# CKMD register map
Vendor: Texas Instruments
Peripheral module from a debugger description file (folder CC23x0R5).
Registers are 32-bit, access per field, reset 0x0 unless marked. A register's access mark holds for its fields unless they carry their own. Offsets are as the file gives them; lines under a group give offsets from that group; [hi:lo] are bit positions; {n}, {i} and the like mark numbered series; 'fields as' and 'values as' point back to an identical list; <NAME> marks a mode.

## CKMD — Clock Controller
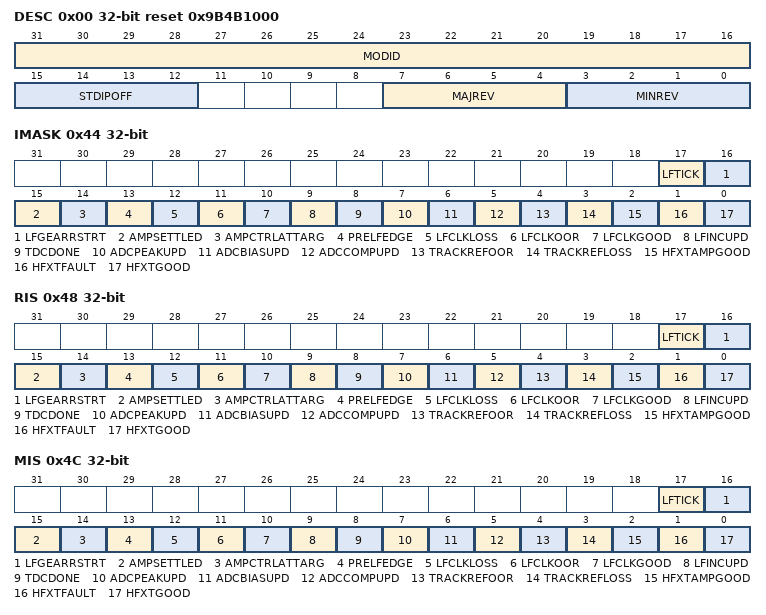
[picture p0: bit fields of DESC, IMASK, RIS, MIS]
0x00 DESC ro reset 0x9B4B1000 — Description Register. This register provides IP module ID, revision information, instance index and standard MMR registers offset.
  [31:16] MODID — Module identifier used to uniquely identify this IP.
  [15:12] STDIPOFF — Standard IP MMR block offset. Standard IP MMRs are the set of from aggregated IRQ registers till DTB. 0: Standard IP MMRs do not exist 0x1-0xF: Standard IP MMRs begin at offset of (64*STDIPOFF from the base IP address) NOTE: This IP does not have DTB as part of the Standard IP MMRs. It uses DTBCTL instead.
  [7:4] MAJREV — Major revision of IP (0-15).
  [3:0] MINREV — Minor revision of IP (0-15).
0x44 IMASK — Interrupt mask. This register selects interrupt sources which are allowed to pass from RIS to MIS when the corresponding bit-fields are set to 1.
  [17] LFTICK rw — 32kHz TICK to RTC and WDT. Either derived from selected LFCLK or generated from CLKULL in absence of LFCLK.
  [16] LFGEARRSTRT rw — LFINC filter gearing restart. Indicates that the LFINC filter restarted gearing. Subsequent LFINC estimates may have higher variation.
  [15] AMPSETTLED rw — HFXT Amplitude compensation - settled Indicates that the amplitude compensation FSM has reached the SETTLED or TCXOMODE state, and the controls configured in HFXTTARG or HFXTDYN are reached.
  [14] AMPCTRLATTARG rw — HFXT Amplitude compensation - controls at target Indicates that the control values configured in HFXTTARG or HFXTDYN are reached. Applies to Q1CAP, Q2CAP and IREF.
  [13] PRELFEDGE rw — Pre-LF clock edge detect. Indicates that a positive edge occured on the selected pre-LF clock LFCLKSEL.PRE. Can be used by software to confirm that a LF clock source is running and within the expected frequency, before selecting it as the main LF clock source.
  [12] LFCLKLOSS rw — LF clock is lost. Indicates that no LF clock edge occured for ~49us (~1.6 times nominal period). The system will automatically fall-back to generating LFTICK based on CLKULL, to avoid timing corruption. Note that this signal is NOT related to the analog LF clock-loss detector which can reset the device during STANDBY.
  [11] LFCLKOOR rw — LF clock period out-of-range. Indicates that a LF clock period was measured to be out-of-range, according to LFQUALCTL.MAXERR.
  [10] LFCLKGOOD rw — LF clock good. Indicates that the LF clock is good, according to the configuration in LFQUALCTL.
  [9] LFINCUPD rw — LFINC updated. Indicates that a new LFINC measurement value is available in LFCLKSTAT.LFINC.
  [8] TDCDONE rw — TDC done event. Indicates that the TDC measurement is done.
  [7] ADCPEAKUPD rw — HFXT-ADC PEAK measurement update event. Indicates that the HFXT-ADC PEAK measurement is done.
  [6] ADCBIASUPD rw — HFXT-ADC BIAS measurement update event. Indicates that the HFXT-ADC BIAS measurement is done.
  [5] ADCCOMPUPD rw — HFXT-ADC comparison update event. Indicates that the HFXT-ADC comparison is done.
  [4] TRACKREFOOR rw — Out-of-range indication from the tracking loop. Indicates that the selected reference clock frequency of the tracking loop is out-of-range.
  [3] TRACKREFLOSS rw — Clock loss indication from the tracking loop. Indicates that the selected reference clock of the tracking loop is lost.
  [2] HFXTAMPGOOD rw — HFXT amplitude good indication.
  [1] HFXTFAULT rw — HFXT fault indication. Indicates that HFXT did not start correctly, or its frequency is too low. HFXT will not recover from this fault and has to be restarted. This is only a one-time check at HFXT startup.
  [0] HFXTGOOD rw — HFXT good indication. Indicates that HFXT started correctly. The frequency is not necessarily good enough for radio operation. This is only a one-time check at HFXT startup.
0x48 RIS ro — Raw interrupt status. This register reflects the state of all pending interrupts, regardless of masking. This register allows the user to implement a poll scheme. A flag set in this register can be cleared by writing 1 to the corresponding ICLR register bit.
  [17] LFTICK — 32kHz TICK to RTC and WDT. Either derived from selected LFCLK or generated from CLKULL in absence of LFCLK.
  [16] LFGEARRSTRT — LFINC filter gearing restart. Indicates that the LFINC filter restarted gearing. Subsequent LFINC estimates may have higher variation.
  [15] AMPSETTLED — HFXT Amplitude compensation - settled Indicates that the amplitude compensation FSM has reached the SETTLED or TCXOMODE state, and the controls configured in HFXTTARG or HFXTDYN are reached.
  [14] AMPCTRLATTARG — HFXT Amplitude compensation - controls at target Indicates that the control values configured in HFXTTARG or HFXTDYN are reached. Applies to Q1CAP, Q2CAP and IREF.
  [13] PRELFEDGE — Pre-LF clock edge detect. Indicates that a positive edge occured on the selected pre-LF clock LFCLKSEL.PRE. Can be used by software to confirm that a LF clock source is running and within the expected frequency, before selecting it as the main LF clock source.
  [12] LFCLKLOSS — LF clock is lost. Indicates that no LF clock edge occured for ~49us (~1.6 times nominal period). The system will automatically fall-back to generating LFTICK based on CLKULL, to avoid timing corruption. Note that this signal is NOT related to the analog LF clock-loss detector which can reset the device during STANDBY.
  [11] LFCLKOOR — LF clock period out-of-range. Indicates that a LF clock period was measured to be out-of-range, according to LFQUALCTL.MAXERR.
  [10] LFCLKGOOD — LF clock good. Indicates that the LF clock is good, according to the configuration in LFQUALCTL.
  [9] LFINCUPD — LFINC updated. Indicates that a new LFINC measurement value is available in LFCLKSTAT.LFINC.
  [8] TDCDONE — TDC done event. Indicates that the TDC measurement is done.
  [7] ADCPEAKUPD — HFXT-ADC PEAK measurement update event. Indicates that the HFXT-ADC PEAK measurement is done.
  [6] ADCBIASUPD — HFXT-ADC BIAS measurement update event. Indicates that the HFXT-ADC BIAS measurement is done.
  [5] ADCCOMPUPD — HFXT-ADC comparison update event. Indicates that the HFXT-ADC comparison is done.
  [4] TRACKREFOOR — Out-of-range indication from the tracking loop. Indicates that the selected reference clock frequency of the tracking loop is out-of-range.
  [3] TRACKREFLOSS — Clock loss indication from the tracking loop. Indicates that the selected reference clock of the tracking loop is lost.
  [2] HFXTAMPGOOD — HFXT amplitude good indication.
  [1] HFXTFAULT — HFXT fault indication. Indicates that HFXT did not start correctly, or its frequency is too low. HFXT will not recover from this fault and has to be restarted. This is only a one-time check at HFXT startup.
  [0] HFXTGOOD — HFXT good indication. Indicates that HFXT started correctly. The frequency is not necessarily good enough for radio operation. This is only a one-time check at HFXT startup.
0x4C MIS ro — Masked interrupt status. This register is simply a bitwise AND of the contents of IMASK and RIS.*] registers. A flag set in this register can be cleared by writing 1 to the corresponding ICLR register bit.
  fields as RIS
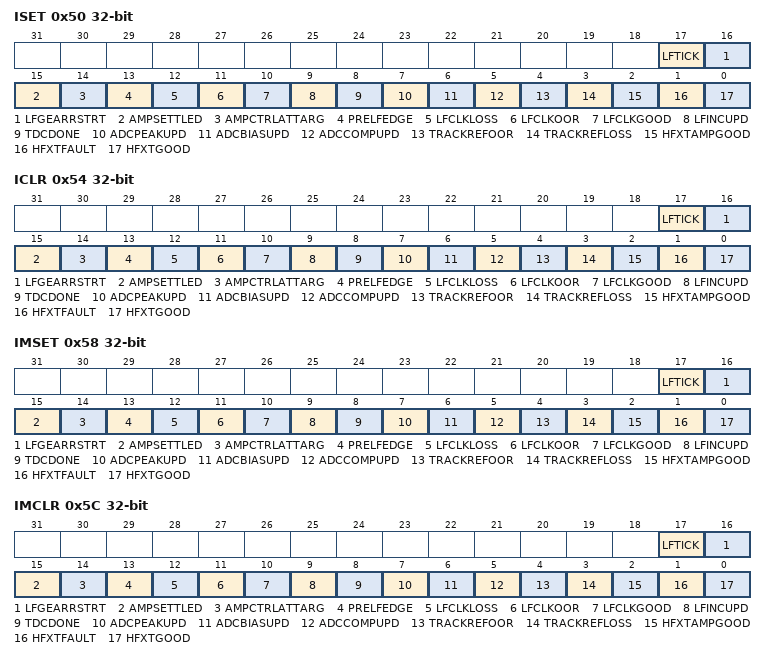
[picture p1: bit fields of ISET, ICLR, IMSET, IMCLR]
0x50 ISET — Interrupt set register. This register can used by software for diagnostics and safety checking purposes. Writing a 1 to a bit in this register will set the event and the corresponding RIS bit also gets set. If the corresponding IMASK bit is set, then the corresponding MIS register bit also gets set.
  [17] LFTICK wo — 32kHz TICK to RTC and WDT. Either derived from selected LFCLK or generated from CLKULL in absence of LFCLK.
  [16] LFGEARRSTRT wo — LFINC filter gearing restart. Indicates that the LFINC filter restarted gearing. Subsequent LFINC estimates may have higher variation.
  [15] AMPSETTLED wo — HFXT Amplitude compensation - settled Indicates that the amplitude compensation FSM has reached the SETTLED or TCXOMODE state, and the controls configured in HFXTTARG or HFXTDYN are reached.
  [14] AMPCTRLATTARG wo — HFXT Amplitude compensation - controls at target Indicates that the control values configured in HFXTTARG.Q1CAP, HFXTTARG.Q2CAP and HFXTTARG.IREF or HFXTDYN.Q1CAP, HFXTDYN.Q2CAP and HFXTDYN.IREF are reached.
  [13] PRELFEDGE wo — Pre-LF clock edge detect. Indicates that a positive edge occured on the selected pre-LF clock LFCLKSEL.PRE. Can be used by software to confirm that a LF clock source is running and within the expected frequency, before selecting it as the main LF clock source.
  [12] LFCLKLOSS wo — LF clock is lost. Indicates that no LF clock edge occured for ~49us (~1.6 times nominal period). The system will automatically fall-back to generating LFTICK based on CLKULL, to avoid timing corruption. Note that this signal is NOT related to the analog LF clock-loss detector which can reset the device during STANDBY.
  [11] LFCLKOOR wo — LF clock period out-of-range. Indicates that a LF clock period was measured to be out-of-range, according to LFQUALCTL.MAXERR.
  [10] LFCLKGOOD wo — LF clock good. Indicates that the LF clock is good, according to the configuration in LFQUALCTL.
  [9] LFINCUPD wo — LFINC updated. Indicates that a new LFINC measurement value is available in LFCLKSTAT.LFINC.
  [8] TDCDONE wo — TDC done event. Indicates that the TDC measurement is done.
  [7] ADCPEAKUPD wo — HFXT-ADC PEAK measurement update event. Indicates that the HFXT-ADC PEAK measurement is done.
  [6] ADCBIASUPD wo — HFXT-ADC BIAS measurement update event. Indicates that the HFXT-ADC BIAS measurement is done.
  [5] ADCCOMPUPD wo — HFXT-ADC comparison update event. Indicates that the HFXT-ADC comparison is done.
  [4] TRACKREFOOR wo — Out-of-range indication from the tracking loop. Indicates that the selected reference clock frequency of the tracking loop is out-of-range.
  [3] TRACKREFLOSS wo — Clock loss indication from the tracking loop. Indicates that the selected reference clock of the tracking loop is lost.
  [2] HFXTAMPGOOD wo — HFXT amplitude good indication.
  [1] HFXTFAULT wo — HFXT fault indication. Indicates that HFXT did not start correctly, or its frequency is too low. HFXT will not recover from this fault and has to be restarted. This is only a one-time check at HFXT startup.
  [0] HFXTGOOD wo — HFXT good indication. Indicates that HFXT started correctly. The frequency is not necessarily good enough for radio operation. This is only a one-time check at HFXT startup.
0x54 ICLR — Interrupt clear register. This register allows software to clear interrupts. Writing a 1 to a bit in this register will clear the event and the corresponding RIS bit also gets cleared. If the corresponding IMASK bit is set, then the corresponding MIS register bit also gets cleared.
  [17] LFTICK wo — 32kHz TICK to RTC and WDT. Either derived from selected LFCLK or generated from CLKULL in absence of LFCLK.
  [16] LFGEARRSTRT wo — LFINC filter gearing restart. Indicates that the LFINC filter restarted gearing. Subsequent LFINC estimates may have higher variation.
  [15] AMPSETTLED wo — HFXT Amplitude compensation - settled Indicates that the amplitude compensation FSM has reached the SETTLED or TCXOMODE state, and the controls configured in HFXTTARG or HFXTDYN are reached.
  [14] AMPCTRLATTARG wo — HFXT Amplitude compensation - controls at target Indicates that the control values configured in HFXTTARG or HFXTDYN are reached. Applies to Q1CAP, Q2CAP and IREF.
  [13] PRELFEDGE wo — Pre-LF clock edge detect. Indicates that a positive edge occured on the selected pre-LF clock LFCLKSEL.PRE. Can be used by software to confirm that a LF clock source is running and within the expected frequency, before selecting it as the main LF clock source.
  [12] LFCLKLOSS wo — LF clock is lost. Indicates that no LF clock edge occured for ~49us (~1.6 times nominal period). The system will automatically fall-back to generating LFTICK based on CLKULL, to avoid timing corruption. Note that this signal is NOT related to the analog LF clock-loss detector which can reset the device during STANDBY.
  [11] LFCLKOOR wo — LF clock period out-of-range. Indicates that a LF clock period was measured to be out-of-range, according to LFQUALCTL.MAXERR.
  [10] LFCLKGOOD wo — LF clock good. Indicates that the LF clock is good, according to the configuration in LFQUALCTL.
  [9] LFINCUPD wo — LFINC updated. Indicates that a new LFINC measurement value is available in LFCLKSTAT.LFINC.
  [8] TDCDONE wo — TDC done event. Indicates that the TDC measurement is done.
  [7] ADCPEAKUPD wo — HFXT-ADC PEAK measurement update event. Indicates that the HFXT-ADC PEAK measurement is done.
  [6] ADCBIASUPD wo — HFXT-ADC BIAS measurement update event. Indicates that the HFXT-ADC BIAS measurement is done.
  [5] ADCCOMPUPD wo — HFXT-ADC comparison update event. Indicates that the HFXT-ADC comparison is done.
  [4] TRACKREFOOR wo — Out-of-range indication from the tracking loop. Indicates that the selected reference clock frequency of the tracking loop is out-of-range.
  [3] TRACKREFLOSS wo — Clock loss indication from the tracking loop. Indicates that the selected reference clock of the tracking loop is lost.
  [2] HFXTAMPGOOD wo — HFXT amplitude good indication.
  [1] HFXTFAULT wo — HFXT fault indication. Indicates that HFXT did not start correctly, or its frequency is too low. HFXT will not recover from this fault and has to be restarted. This is only a one-time check at HFXT startup.
  [0] HFXTGOOD wo — HFXT good indication. Indicates that HFXT started correctly. The frequency is not necessarily good enough for radio operation. This is only a one-time check at HFXT startup.
0x58 IMSET — Interrupt mask set register. Writing a 1 to a bit in this register will set the corresponding IMASK bit.
  fields as ICLR
0x5C IMCLR — Interrupt mask clear register. Writing a 1 to a bit in this register will clear the corresponding IMASK bit.
  fields as ICLR
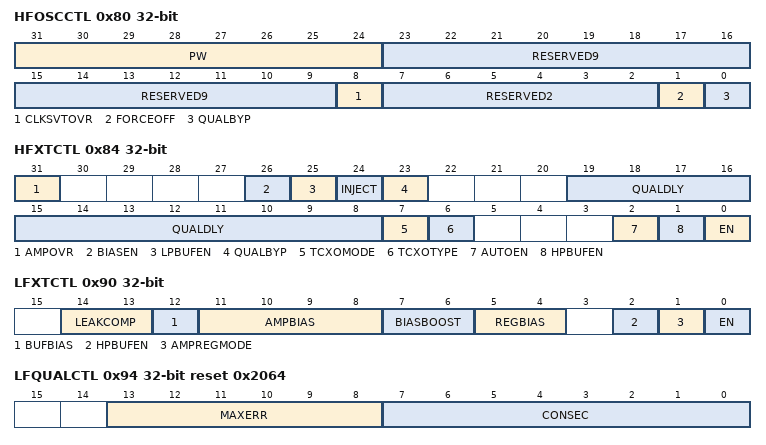
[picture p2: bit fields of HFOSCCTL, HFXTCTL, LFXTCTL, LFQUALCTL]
0x80 HFOSCCTL — Internal. Only to be used through TI provided API.
  [31:24] PW wo — Internal. Only to be used through TI provided API.
  [23:9] RESERVED9 ro — Internal. Only to be used through TI provided API.
  [8] CLKSVTOVR rw — Internal. Only to be used through TI provided API.
    1=HFXT (Internal. Only to be used through TI provided API.); 0=HFOSC (Internal. Only to be used through TI provided API.)
  [7:2] RESERVED2 ro — Internal. Only to be used through TI provided API.
  [1] FORCEOFF rw — Internal. Only to be used through TI provided API.
  [0] QUALBYP rw — Internal. Only to be used through TI provided API.
0x84 HFXTCTL — High frequency crystal control
  [31] AMPOVR rw — Internal. Only to be used through TI provided API.
  [26] BIASEN rw — Internal. Only to be used through TI provided API.
  [25] LPBUFEN rw — Internal. Only to be used through TI provided API.
  [24] INJECT rw — Internal. Only to be used through TI provided API.
  [23] QUALBYP rw — Internal. Only to be used through TI provided API.
  [19:8] QUALDLY rw — Skip potentially unstable clock cycles after enabling HFXT. Number of cycles skipped is 8*QUALDLY.
  [7] TCXOMODE rw — Temperature compensated crystal oscillator mode. Set this bit if a TXCO is connected.
  [6] TCXOTYPE rw — Type of temperature compensated crystal used. Only has effect if TCXOMODE is set.
    1=CMOS (Use with CMOS TCXO); 0=CLIPPEDSINE (Use with clipped-sine TCXO)
  [2] AUTOEN rw — Internal. Only to be used through TI provided API.
  [1] HPBUFEN rw — High performance clock buffer enable. This bit controls the clock output for the RF PLL. It is required for radio operation.
  [0] EN rw — Internal. Only to be used through TI provided API.
0x8C LFOSCCTL — Low frequency oscillator control
  [0] EN rw — LFOSC enable
0x90 LFXTCTL — Low frequency crystal control
  [14:13] LEAKCOMP rw — Leakage compensation control
    3=OFF (No leakage compensation); 1=HALF (Half leakage compensation); 0=FULL (Full leakage compensation)
  [12] BUFBIAS rw — Control the BIAS current of the input amp in LP buffer
    1=MAX (Maximum bias current: 50nA); 0=MIN (Minimum bias current: 25nA)
  [11:8] AMPBIAS rw — Adjust current mirror ratio into oscillator core. This value is depending on crystal and is set by FW. This field uses a 2's complement encoding.
  [7:6] BIASBOOST rw — Boost oscillator amplitude This value depends on the crystal and needs to be configured by Firmware.
  [5:4] REGBIAS rw — Regulation loop bias resistor value This value depends on the crystal and needs to be configured by Firmware.
  [2] HPBUFEN rw — Control the buffer used. In normal operation, low-power buffer is used in all device modes. The high-performance buffer is only used for test purposes.
  [1] AMPREGMODE rw — Amplitude regulation mode
    1=LOOPDIS (Amplitude control loop disabled); 0=LOOPEN (Amplitude control loop enabled)
  [0] EN rw — LFXT enable
0x94 LFQUALCTL reset 0x2064 — Low frequency clock qualification control
  [13:8] MAXERR rw — Maximum LFCLK period error. Value given in microseconds, 3 integer bits + 3 fractional bits.
  [7:0] CONSEC rw — Number of consecutive times the LFCLK period error has to be smaller than MAXERR to be considered "good". Setting this value to 0 will bypass clock qualification, and the "good" indicator will always be 1.
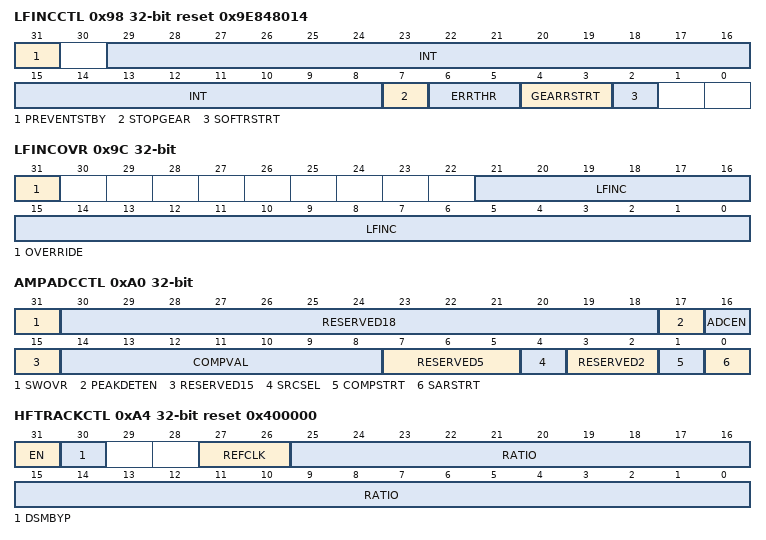
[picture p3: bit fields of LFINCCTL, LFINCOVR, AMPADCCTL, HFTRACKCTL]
0x98 LFINCCTL reset 0x9E848014 — Low frequency time increment control
  [31] PREVENTSTBY rw — Controls if the LFINC filter prevents STANBY entry until settled.
    1=ON (Enable. Prevent STANDBY entry.); 0=OFF (Disable. Do not prevent STANDBY entry.)
  [29:8] INT rw — Integral part of the LFINC filter. This value is updated by Hardware to reflect the current state of the filter. It can also be written to change the current state.
  [7] STOPGEAR rw — Controls the final gear of the LFINC filter.
    1=HIGH (Highest final gear. Best dynamic frequency tracking, but higher variation in filter value.); 0=LOW (Lowest final gear. Best settling, but less dynamic frequency tracking.)
  [6:5] ERRTHR rw — Controls the threshold for gearing restart of the LFINC filter. Only effective if GEARRSTRT is not ONETHR or TWOTHR.
    3=SMALL (Restart gearing on small error. Potentially more false restarts, faster response on small frequency shifts.); 2=MIDSMALL (Middle value towards SMALL.); 1=MIDLARGE (Middle value towards LARGE.); 0=LARGE (Restart gearing on large error. Fewer false restarts, slower response on small frequency shifts.)
  [4:3] GEARRSTRT rw — Controls gearing restart of the LFINC filter.
    2=TWOTHR (Restart gearing when the error accumulator crosses the threshold twice in a row.); 1=ONETHR (Restart gearing when the error accumulator crosses the threshold once.); 0=NEVER (Never restart gearing. Very stable filter value, but very slow response on frequency changes.)
  [2] SOFTRSTRT rw — Use a higher gear after re-enabling / wakeup. The filter will require 16-24 LFCLK periods to settle (depending on STOPGEAR), but may respond faster to frequency changes during STANDBY.
    1=ON (Use soft gearing restarts); 0=OFF (Don't use soft gearing restarts)
0x9C LFINCOVR — Low frequency time increment override control
  [31] OVERRIDE rw — Override LF increment Use the value provided in LFINC instead of the value calculated by Hardware.
  [21:0] LFINC rw — LF increment value This value is used when OVERRIDE is set to 1. Otherwise the value is calculated automatically.
0xA0 AMPADCCTL — Internal. Only to be used through TI provided API.
  [31] SWOVR rw — Internal. Only to be used through TI provided API.
  [30:18] RESERVED18 ro — Internal. Only to be used through TI provided API.
  [17] PEAKDETEN rw — Internal. Only to be used through TI provided API.
    1=ENABLE (Internal. Only to be used through TI provided API.); 0=DISABLE (Internal. Only to be used through TI provided API.)
  [16] ADCEN rw — Internal. Only to be used through TI provided API.
    values as PEAKDETEN
  [15] RESERVED15 ro — Internal. Only to be used through TI provided API.
  [14:8] COMPVAL rw — Internal. Only to be used through TI provided API.
  [7:5] RESERVED5 ro — Internal. Only to be used through TI provided API.
  [4] SRCSEL rw — Internal. Only to be used through TI provided API.
    1=PEAK (Internal. Only to be used through TI provided API.); 0=BIAS (Internal. Only to be used through TI provided API.)
  [3:2] RESERVED2 ro — Internal. Only to be used through TI provided API.
  [1] COMPSTRT rw — Internal. Only to be used through TI provided API.
  [0] SARSTRT rw — Internal. Only to be used through TI provided API.
0xA4 HFTRACKCTL reset 0x400000 — High frequency tracking loop control
  [31] EN rw — Enable tracking loop.
  [30] DSMBYP rw — Bypass Delta-Sigma-Modulation of fine trim.
  [27:26] REFCLK rw — Select the reference clock for the tracking loop. Change only while the tracking loop is disabled.
    2=GPI (Select GPI as reference clock.); 1=LRF (Select LRF reference clock.); 0=HFXT (Select HFXT as reference clock.)
  [25:0] RATIO rw — Reference clock ratio. RATIO = 24MHz / (2*reference-frequency) * 2^24 Commonly used reference clock frequencies are provided as enumerations.
    0x3000000=REF4M (Use for 4MHz reference clock); 0x1800000=REF8M (Use for 8MHz reference clock); 0x400000=REF48M (Use for 48MHz reference clock)
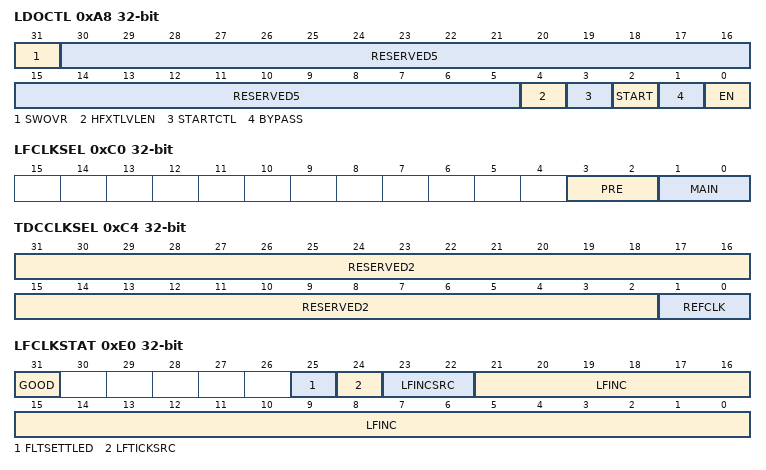
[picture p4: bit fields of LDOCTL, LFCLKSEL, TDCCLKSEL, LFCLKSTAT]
0xA8 LDOCTL — Internal. Only to be used through TI provided API.
  [31] SWOVR rw — Internal. Only to be used through TI provided API.
  [30:5] RESERVED5 ro — Internal. Only to be used through TI provided API.
  [4] HFXTLVLEN rw — Internal. Only to be used through TI provided API.
  [3] STARTCTL rw — Internal. Only to be used through TI provided API.
  [2] START rw — Internal. Only to be used through TI provided API.
  [1] BYPASS rw — Internal. Only to be used through TI provided API.
  [0] EN rw — Internal. Only to be used through TI provided API.
0xAC NABIASCTL — Nanoamp-bias control
  [0] EN rw — Enable nanoamp-bias
0xB0 LFMONCTL — Low-frequency clock-monitor control
  [0] EN rw — Enable LFMONITOR. Enable only after a LF clock source has been selected, enabled and is stable. If LFMONITOR detects a clock loss, the system will be reset.
0xC0 LFCLKSEL — Low frequency clock selection
  [3:2] PRE rw — Select low frequency clock source for the PRELFCLK interrupt. Can be used by Software to confirm that the clock is running and it's frequency is good, before selecting it in MAIN.
    3=EXTLF (External LF clock through GPI.); 2=LFXT (Low frequency crystal oscillator); 1=LFOSC (Low frequency on-chip oscillator); 0=NONE (No clock. Output will be tied low.)
  [1:0] MAIN rw — Select the main low frequency clock source. If running, this clock will be used to generate LFTICK and as CLKULL during STANDBY. If not running, LFTICK will be generated from HFOSC and STANDBY entry will be prevented.
    3=EXTLF (External LF clock through GPI.); 2=LFXT (Low frequency crystal oscillator); 1=LFOSC (Low frequency on-chip oscillator); 0=FAKE (No LF clock selected. LFTICK will be generated from HFOSC, STANDBY entry will be prevented.)
0xC4 TDCCLKSEL — Internal. Only to be used through TI provided API.
  [31:2] RESERVED2 ro — Internal. Only to be used through TI provided API.
  [1:0] REFCLK rw — Internal. Only to be used through TI provided API.
    3=GPI (Internal. Only to be used through TI provided API.); 2=CLKULL (Internal. Only to be used through TI provided API.); 1=CLKSVT (Internal. Only to be used through TI provided API.); 0=NONE (Internal. Only to be used through TI provided API.)
0xC8 ADCCLKSEL — ADC clock selection
  [1:0] SRC rw — Select ADC clock source Change only while ADC is disabled.
    1=HFXT (48MHz HFXT); 0=CLKSVT (48MHz CLKSVT)
0xE0 LFCLKSTAT ro — Low-frequency clock status
  [31] GOOD — Low frequency clock good Note: This is only a coarse frequency check based on LFQUALCTL. The clock may not be accurate enough for timing purposes.
  [25] FLTSETTLED — LFINC filter is running and settled.
  [24] LFTICKSRC — Source of LFTICK.
    1=FAKE (LFTICK generated from CLKULL (LFCLK not available)); 0=LFCLK (LFTICK generated from the selected LFCLK)
  [23:22] LFINCSRC — Source of LFINC used by the RTC. This value depends on LFINCOVR.OVERRIDE, LF clock availability, HF tracking loop status and the device state (ACTIVE/STANDBY).
    3=FAKE (Using FAKE LFTICKs with corresponding LFINC value.); 2=OVERRIDE (Using override value from LFINCOVR.LFINC); 1=AVG (Using filtered / average value. This value is updated by hardware and can be read and updated in LFINCCTL.INT.); 0=MEAS (Using measured value. This value is updated by hardware and can be read from LFINC.)
  [21:0] LFINC — Measured value of LFINC. Given in microseconds with 16 fractional bits. This value is calculated by Hardware. It is the LFCLK period according to CLKULL cycles.
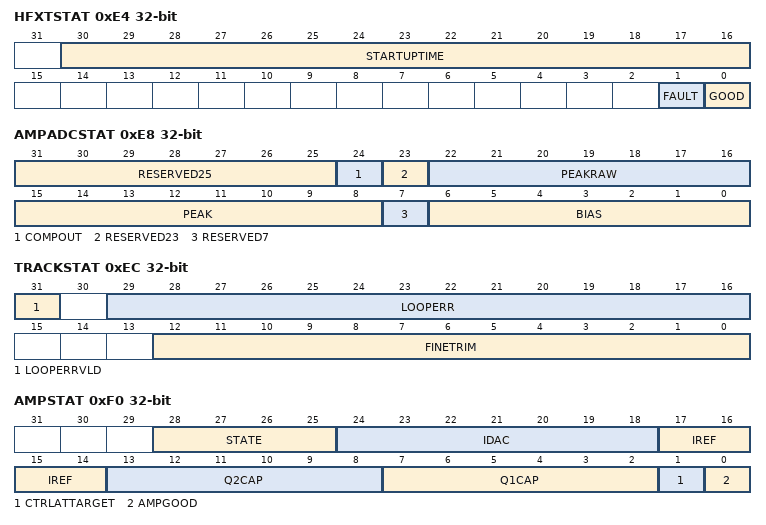
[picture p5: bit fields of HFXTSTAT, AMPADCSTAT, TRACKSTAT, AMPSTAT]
0xE4 HFXTSTAT ro — HFXT status information
  [30:16] STARTUPTIME — HFXT startup time Can be used by software to plan starting HFXT ahead in time. Measured whenever HFXT is enabled in CLKULL periods (24MHz), from HFXTCTL.EN until the clock is good for radio operation (amplitude compensation is settled).
  [1] FAULT — HFXT clock fault Indicates a lower than expected HFXT frequency. HFXT will not recover from this fault, disabling and re-enabling HFXT is required.
  [0] GOOD — HFXT clock available. The frequency is not necessarily good enough for radio operation.
0xE8 AMPADCSTAT ro — Internal. Only to be used through TI provided API.
  [31:25] RESERVED25 — Internal. Only to be used through TI provided API.
  [24] COMPOUT — Internal. Only to be used through TI provided API.
  [23] RESERVED23 — Internal. Only to be used through TI provided API.
  [22:16] PEAKRAW — Internal. Only to be used through TI provided API.
  [15:8] PEAK — Internal. Only to be used through TI provided API.
  [7] RESERVED7 — Internal. Only to be used through TI provided API.
  [6:0] BIAS — Internal. Only to be used through TI provided API.
0xEC TRACKSTAT ro — HFOSC tracking loop status information
  [31] LOOPERRVLD — Current HFOSC tracking error valid This bit is one if the tracking loop is running and the error value is valid.
  [29:16] LOOPERR — Current HFOSC tracking error
  [12:0] FINETRIM — Current HFOSC Fine-trim value This field uses the internal fractional representation (sign, 4 integer bits, 8 fractional bits). The actual trim value applied to the oscillator is delta-sigma modulated 5 bits non-signed (inverted sign bit + integer bits).
0xF0 AMPSTAT ro — HFXT Amplitude Compensation Status
  [28:25] STATE — Current AMPCOMP FSM state.
    15=SETTLED (Settled state); 14=UPDATEUP (Amplitude up correction); 12=TXCOMODE (TCXO settled state); 10=SHUTDN0 (First shutdown state); 7=INJWAIT (Post injection settle wait); 6=UPDATEDN (Amplitude down correction); 5=RAMP0 (Initial amplitude ramping with HFXTINIT values); 4=RAMP1 (Transition to HFXTTARG values); 3=INJECT (Injecting HFOSC for fast startup); 2=SHUTDN1 (Second shutdown state); 1=LDOSTART (Starting LDO); 0=IDLE (FSM in idle state)
  [24:18] IDAC — Current IDAC control value.
  [17:14] IREF — Current IREF control value.
  [13:8] Q2CAP — Current Q2CAP control value.
  [7:2] Q1CAP — Current Q1CAP control value.
  [1] CTRLATTARGET — HFXT control values match target values. This applies to IREF, Q1CAP, Q2CAP values.
  [0] AMPGOOD — HFXT amplitude good
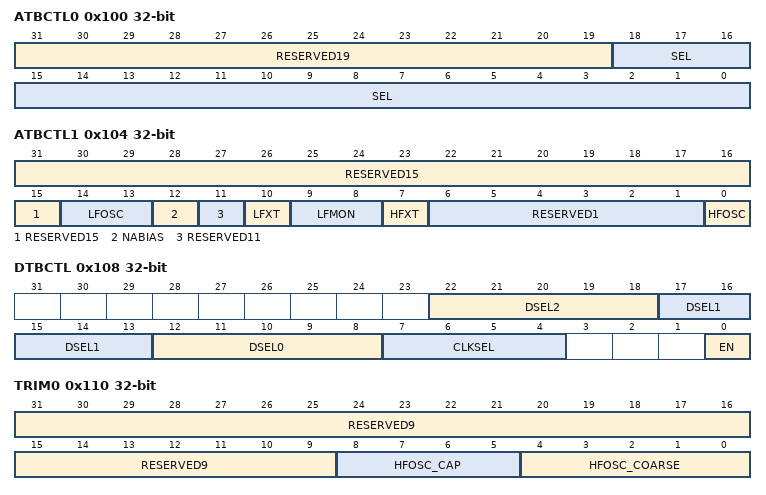
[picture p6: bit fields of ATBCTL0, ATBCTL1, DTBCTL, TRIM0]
0x100 ATBCTL0 — Internal. Only to be used through TI provided API.
  [31:19] RESERVED19 ro — Internal. Only to be used through TI provided API.
  [18:0] SEL rw — Internal. Only to be used through TI provided API.
    0x70000=LFXTTESTCLK (Internal. Only to be used through TI provided API.); 0x50000=LFOSCTESTCLK (Internal. Only to be used through TI provided API.); 0x30000=HFXTTESTCLK (Internal. Only to be used through TI provided API.); 0x10000=HFOSCTESTCLK (Internal. Only to be used through TI provided API.); 0x1000=LFMONVTEST (Internal. Only to be used through TI provided API.); 0x800=LFOSCVDDL (Internal. Only to be used through TI provided API.); 0x400=HFOSCIBIAS (Internal. Only to be used through TI provided API.); 0x200=HFOSCVDDL (Internal. Only to be used through TI provided API.); 0x100=HFOSCVREF (Internal. Only to be used through TI provided API.); 128=NABIASITEST (Internal. Only to be used through TI provided API.); 64=ADCDACOUT (Internal. Only to be used through TI provided API.); 32=ADCCOMPIN (Internal. Only to be used through TI provided API.); 16=ADCCOMPOUT (Internal. Only to be used through TI provided API.); 8=LFXTANA (Internal. Only to be used through TI provided API.); 4=LDOITEST (Internal. Only to be used through TI provided API.); 2=VDDCKM (Internal. Only to be used through TI provided API.); 1=HFXTANA (Internal. Only to be used through TI provided API.); 0=OFF (Internal. Only to be used through TI provided API.)
0x104 ATBCTL1 — Internal. Only to be used through TI provided API.
  [31:15] RESERVED15 ro — Internal. Only to be used through TI provided API.
  [14:13] LFOSC rw — Internal. Only to be used through TI provided API.
    3=BOTH (Internal. Only to be used through TI provided API.); 2=VDDLOCAL (Internal. Only to be used through TI provided API.); 1=TESTCLK (Internal. Only to be used through TI provided API.); 0=OFF (Internal. Only to be used through TI provided API.)
  [12] NABIAS rw — Internal. Only to be used through TI provided API.
  [11] RESERVED11 ro — Internal. Only to be used through TI provided API.
  [10] LFXT rw — Internal. Only to be used through TI provided API.
    1=TESTCLK (Internal. Only to be used through TI provided API.); 0=OFF (Internal. Only to be used through TI provided API.)
  [9:8] LFMON rw — Internal. Only to be used through TI provided API.
    2=TEST2 (Internal. Only to be used through TI provided API.); 1=TEST1 (Internal. Only to be used through TI provided API.); 0=OFF (Internal. Only to be used through TI provided API.)
  [7] HFXT rw — Internal. Only to be used through TI provided API.
  [6:1] RESERVED1 ro — Internal. Only to be used through TI provided API.
  [0] HFOSC rw — Internal. Only to be used through TI provided API.
0x108 DTBCTL — Digital test bus mux control
  [22:18] DSEL2 rw — Internal. Only to be used through TI provided API.
  [17:13] DSEL1 rw — Internal. Only to be used through TI provided API.
  [12:8] DSEL0 rw — Internal. Only to be used through TI provided API.
  [7:4] CLKSEL rw — Select clock to output on DTB[0]
    15=LFXT (Select LFXT); 14=LFOSC (Select LFOSC); 13=HFXT (Select HFXT); 12=HFXTBY8 (Select HFXT divided by 8); 10=HFOSC (Select HFOSC after qualification); 7=LFCLK (Select LFCLK (selected by LFCLKSEL.MAIN)); 4=TRACKREF (Select tracking loop reference clock); 2=CLKADC (Select CLKADC (48 MHz)); 1=CLKSVT (Select CLKSVT (48 MHz)); 0=CLKULL (Select CLKULL (24 MHz during ACTIVE, 32kHz during STANDBY))
  [0] EN rw — Enable DTB output
0x110 TRIM0 — Internal. Only to be used through TI provided API.
  [31:9] RESERVED9 ro — Internal. Only to be used through TI provided API.
  [8:5] HFOSC_CAP rw — Internal. Only to be used through TI provided API.
  [4:0] HFOSC_COARSE rw — Internal. Only to be used through TI provided API.
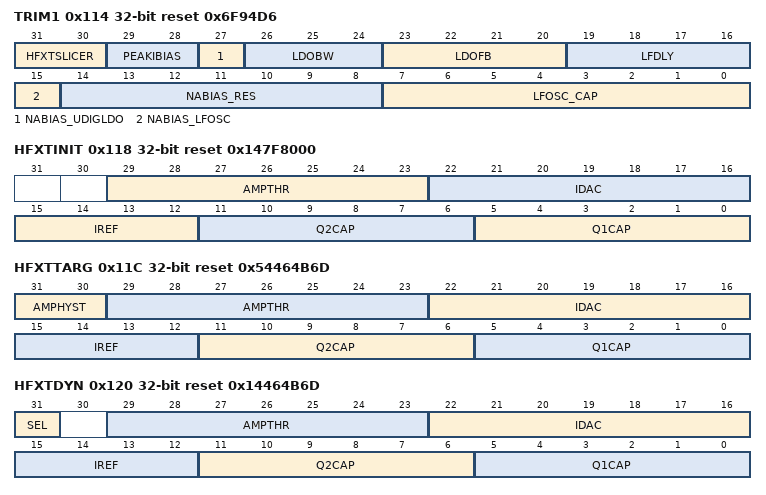
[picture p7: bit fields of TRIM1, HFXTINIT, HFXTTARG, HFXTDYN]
0x114 TRIM1 rw reset 0x6F94D6 — Internal. Only to be used through TI provided API.
  [31:30] HFXTSLICER — Internal. Only to be used through TI provided API.
  [29:28] PEAKIBIAS — Internal. Only to be used through TI provided API.
  [27] NABIAS_UDIGLDO — Internal. Only to be used through TI provided API.
  [26:24] LDOBW — Internal. Only to be used through TI provided API.
  [23:20] LDOFB — Internal. Only to be used through TI provided API.
  [19:16] LFDLY — Internal. Only to be used through TI provided API.
  [15] NABIAS_LFOSC — Internal. Only to be used through TI provided API.
  [14:8] NABIAS_RES — Internal. Only to be used through TI provided API.
  [7:0] LFOSC_CAP — Internal. Only to be used through TI provided API.
0x118 HFXTINIT reset 0x147F8000 — Initial values for HFXT ramping
  [29:23] AMPTHR rw — Amplitude threshold during HFXT ramping
  [22:16] IDAC rw — Initial HFXT IDAC current
  [15:12] IREF rw — Initial HFXT IREF current
  [11:6] Q2CAP rw — Initial HFXT Q2 cap trim
  [5:0] Q1CAP rw — Initial HFXT Q1 cap trim
0x11C HFXTTARG rw reset 0x54464B6D — Target values for HFXT ramping
  [31:30] AMPHYST — ADC hysteresis used during IDAC updates. Every AMPCFG1.INTERVAL, IDAC will be regulated - up as long as ADC $lt; AMPTHR - down as long as ADC $gt; AMPTHR+AMPHYST
  [29:23] AMPTHR — Minimum HFXT amplitude
  [22:16] IDAC — Minimum IDAC current
  [15:12] IREF — Target HFXT IREF current
  [11:6] Q2CAP — Target HFXT Q2 cap trim
  [5:0] Q1CAP — Target HFXT Q1 cap trim
0x120 HFXTDYN reset 0x14464B6D — Alternative target values for HFXT configuration Software can change these values to dynamically transition the HFXT configuration while HFXT is running. Set SEL to select the alternative set of target values.
  [31] SEL rw — Select the dynamic configuration. Amplitude ramping will always happen using the values in HFXTINIT, and HFXTTARG. Afterwards, this bit can be used to select between HFXTTARG and HFXTDYN. Hardware will ensure a smooth transition of analog control signals.
    1=DYNAMIC (Select configuration in HFXTDYN.); 0=TARGET (Select configuration in HFXTTARG.)
  [29:23] AMPTHR rw — Minimum HFXT amplitude
  [22:16] IDAC rw — Minimum IDAC current
  [15:12] IREF rw — Target HFXT IREF current
  [11:6] Q2CAP rw — Target HFXT Q2 cap trim
  [5:0] Q1CAP rw — Target HFXT Q1 cap trim
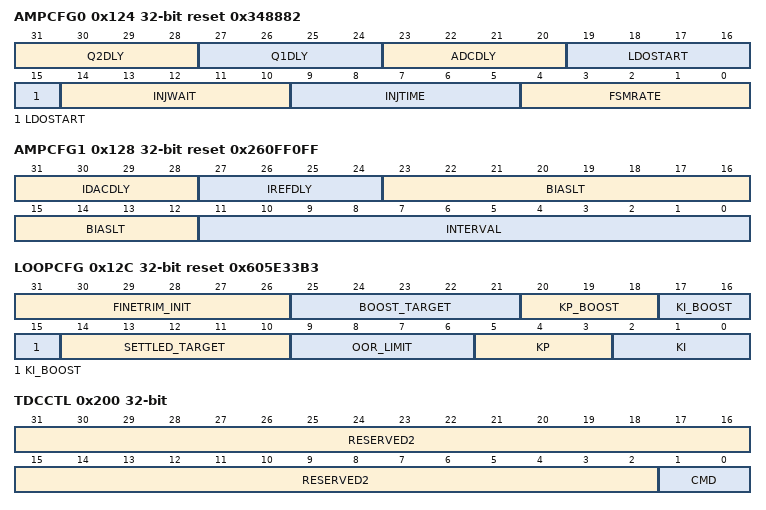
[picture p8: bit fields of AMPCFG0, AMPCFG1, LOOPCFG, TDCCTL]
0x124 AMPCFG0 rw reset 0x348882 — Amplitude Compensation Configuration 0
  [31:28] Q2DLY — Q2CAP change delay. Number of clock cycles to wait before changing Q2CAP by one step. Clock frequency defined in FSMRATE.
  [27:24] Q1DLY — Q1CAP change delay. Number of clock cycles to wait before changing Q1CAP by one step. Clock frequency defined in FSMRATE.
  [23:20] ADCDLY — ADC and PEAKDET startup time. Number of clock cycles to wait after enabling the PEAKDET and ADC before the first measurement. Clock frequency defined in FSMRATE.
  [19:15] LDOSTART — LDO startup time. Number of clock cycles to bypass the LDO resistors for faster startup. Clock frequency defined in FSMRATE.
  [14:10] INJWAIT — Inject HFOSC for faster HFXT startup. This value specifies the number of clock cycles to wait after injection is done. The clock speed is defined in FSMRATE.
  [9:5] INJTIME — Inject HFOSC for faster HFXT startup. This value specifies the number of clock cycles the injection is enabled. The clock speed is defined in FSMRATE. Set to 0 to disable injection.
  [4:0] FSMRATE — Update rate for the AMPCOMP update rate. Also affects the clock rate for the Amplitude ADC. The update rate is 6MHz / (FSMRATE+1).
    23=250 kHz; 11=500 kHz; 5=1 MHz; 2=2 MHz; 1=3 MHz; 0=6 MHz
0x128 AMPCFG1 rw reset 0x260FF0FF — Amplitude Compensation Configuration 1
  [31:28] IDACDLY — IDAC change delay. Time to wait before changing IDAC by one step. This time needs to be long enough for the crystal to settle. The number of clock cycles to wait is IDACDLY$lt;$lt;4 + 15. Clock frequency defined in AMPCFG0.FSMRATE.
  [27:24] IREFDLY — IREF change delay. Number of clock cycles to wait before changing IREF by one step. Clock frequency defined in AMPCFG0.FSMRATE.
  [23:12] BIASLT — Lifetime of the amplitude ADC bias value. This value specifies the number of adjustment intervals, until the ADC bias value has to be measured again. Set to 0 to disable automatic bias measurements.
  [11:0] INTERVAL — Interval for amplitude adjustments. Set to 0 to disable periodic adjustments. This value specifies the number of clock cycles between adjustments. The clock speed is defined in AMPCFG0.FSMRATE.
0x12C LOOPCFG rw reset 0x605E33B3 — Configuration Register for the Tracking Loop
  [31:26] FINETRIM_INIT — Initial value for the resistor fine trim
  [25:21] BOOST_TARGET — Number of error-updates using BOOST values, before using KI/KP
  [20:18] KP_BOOST — Proportional loop coefficient during BOOST
  [17:15] KI_BOOST — Integral loop coefficient during BOOST
  [14:10] SETTLED_TARGET — Number of updates before HFOSC is considered "settled"
  [9:6] OOR_LIMIT — Out-of-range threshold
  [5:3] KP — Proportional loop coefficient
  [2:0] KI — Integral loop coefficient
0x200 TDCCTL — Internal. Only to be used through TI provided API.
  [31:2] RESERVED2 ro — Internal. Only to be used through TI provided API.
  [1:0] CMD wo — Internal. Only to be used through TI provided API.
    3=ABORT (Internal. Only to be used through TI provided API.); 2=RUN (Internal. Only to be used through TI provided API.); 1=RUN_SYNC_START (Internal. Only to be used through TI provided API.); 0=CLR_RESULT (Internal. Only to be used through TI provided API.)
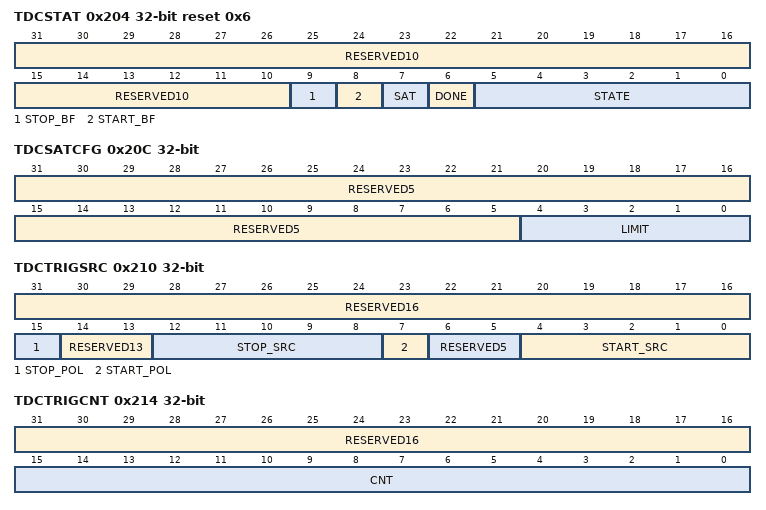
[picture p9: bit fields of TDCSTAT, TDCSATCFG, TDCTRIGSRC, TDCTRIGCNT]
0x204 TDCSTAT ro reset 0x6 — Internal. Only to be used through TI provided API.
  [31:10] RESERVED10 — Internal. Only to be used through TI provided API.
  [9] STOP_BF — Internal. Only to be used through TI provided API.
  [8] START_BF — Internal. Only to be used through TI provided API.
  [7] SAT — Internal. Only to be used through TI provided API.
  [6] DONE — Internal. Only to be used through TI provided API.
  [5:0] STATE — Internal. Only to be used through TI provided API.
    46=FORCE_STOP (Internal. Only to be used through TI provided API.); 30=START_FALL (Internal. Only to be used through TI provided API.); 22=WAIT_CLR_CNT_DONE (Internal. Only to be used through TI provided API.); 15=POR (Internal. Only to be used through TI provided API.); 14=GET_RESULT (Internal. Only to be used through TI provided API.); 12=WAIT_STOP_CNTDWN (Internal. Only to be used through TI provided API.); 8=WAIT_STOP (Internal. Only to be used through TI provided API.); 7=CLR_CNT (Internal. Only to be used through TI provided API.); 6=IDLE (Internal. Only to be used through TI provided API.); 4=WAIT_START_STOP_CNT_EN (Internal. Only to be used through TI provided API.); 0=WAIT_START (Internal. Only to be used through TI provided API.)
0x208 TDCRESULT ro reset 0x2 — Internal. Only to be used through TI provided API.
  [31:0] VALUE
0x20C TDCSATCFG — Internal. Only to be used through TI provided API.
  [31:5] RESERVED5 ro — Internal. Only to be used through TI provided API.
  [4:0] LIMIT rw — Internal. Only to be used through TI provided API.
    {v}=R{v+9} (Internal. Only to be used through TI provided API.) (v=3..21); 0=NONE (Internal. Only to be used through TI provided API.)
0x210 TDCTRIGSRC — Internal. Only to be used through TI provided API.
  [31:16] RESERVED16 ro — Internal. Only to be used through TI provided API.
  [15] STOP_POL rw — Internal. Only to be used through TI provided API.
    1=LOW (Internal. Only to be used through TI provided API.); 0=HIGH (Internal. Only to be used through TI provided API.)
  [14:13] RESERVED13 ro — Internal. Only to be used through TI provided API.
  [12:8] STOP_SRC rw — Internal. Only to be used through TI provided API.
    31=TDC_PRE (Internal. Only to be used through TI provided API.); {v}=DTB{v-5} (Internal. Only to be used through TI provided API.) (v=5..20); 4=GPI (Internal. Only to be used through TI provided API.); 3=LFCLK_DLY (Internal. Only to be used through TI provided API.); 2=LFXT (Internal. Only to be used through TI provided API.); 1=LFOSC (Internal. Only to be used through TI provided API.); 0=LFTICK (Internal. Only to be used through TI provided API.)
  [7] START_POL rw — Internal. Only to be used through TI provided API.
    values as STOP_POL
  [6:5] RESERVED5 ro — Internal. Only to be used through TI provided API.
  [4:0] START_SRC rw — Internal. Only to be used through TI provided API.
    values as STOP_SRC
0x214 TDCTRIGCNT — Internal. Only to be used through TI provided API.
  [31:16] RESERVED16 ro — Internal. Only to be used through TI provided API.
  [15:0] CNT rw — Internal. Only to be used through TI provided API.
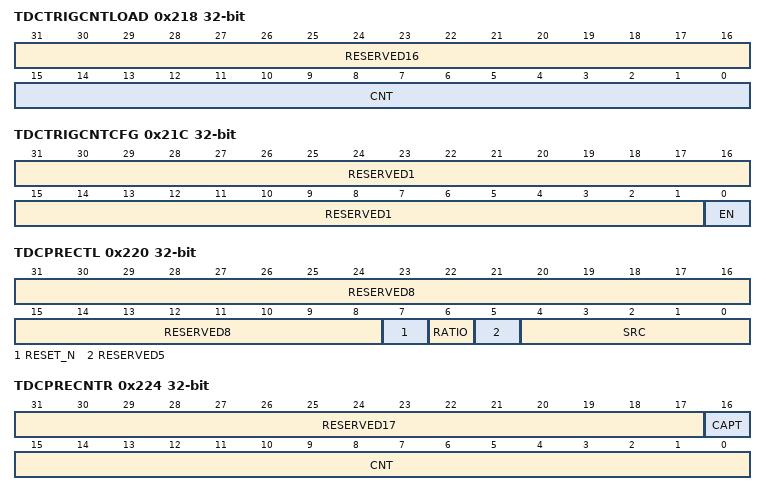
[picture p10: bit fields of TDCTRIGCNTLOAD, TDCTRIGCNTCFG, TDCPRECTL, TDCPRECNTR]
0x218 TDCTRIGCNTLOAD — Internal. Only to be used through TI provided API.
  fields as TDCTRIGCNT
0x21C TDCTRIGCNTCFG — Internal. Only to be used through TI provided API.
  [31:1] RESERVED1 ro — Internal. Only to be used through TI provided API.
  [0] EN rw — Internal. Only to be used through TI provided API.
0x220 TDCPRECTL — Internal. Only to be used through TI provided API.
  [31:8] RESERVED8 ro — Internal. Only to be used through TI provided API.
  [7] RESET_N rw — Internal. Only to be used through TI provided API.
  [6] RATIO rw — Internal. Only to be used through TI provided API.
    1=DIV64 (Internal. Only to be used through TI provided API.); 0=DIV16 (Internal. Only to be used through TI provided API.)
  [5] RESERVED5 ro — Internal. Only to be used through TI provided API.
  [4:0] SRC rw — Internal. Only to be used through TI provided API.
    22=HFXT (Internal. Only to be used through TI provided API.); 21=HFOSC (Internal. Only to be used through TI provided API.); {v}=DTB{v-5} (Internal. Only to be used through TI provided API.) (v=5..20); 4=GPI (Internal. Only to be used through TI provided API.); 3=LFCLK_DLY (Internal. Only to be used through TI provided API.); 2=LFXT (Internal. Only to be used through TI provided API.); 1=LFOSC (Internal. Only to be used through TI provided API.); 0=LFTICK (Internal. Only to be used through TI provided API.)
0x224 TDCPRECNTR — Internal. Only to be used through TI provided API.
  [31:17] RESERVED17 ro — Internal. Only to be used through TI provided API.
  [16] CAPT wo — Internal. Only to be used through TI provided API.
  [15:0] CNT ro — Internal. Only to be used through TI provided API.
0x300 WDTCNT rw — WDT counter value register
  [31:0] VAL — Counter value. A write to this field immediately starts (or restarts) the counter. It will count down from the written value. If the counter reaches 0, a reset will be generated. A write value of 0 immediately generates a reset. This field is only writable if not locked. See WDTLOCK register. Writing this field will automatically activate the lock. A read returns the current value of the counter.
0x304 WDTTEST — WDT test mode register
  [0] STALLEN rw — WDT stall enable This field is only writable if not locked. See WDTLOCK register.
    1=EN (ENABLE WDT stops counting while the CPU is stopped by a debugger.); 0=DIS (DISABLE WDT continues counting while the CPU is stopped by a debugger.)
0x308 WDTLOCK rw reset 0x1
  [31:0] STAT — A write with value 0x1ACCE551 unlocks the watchdog registers for write access. A write with any other value locks the watchdog registers for write access. Writing the WDTCNT register will also lock the watchdog registers. A read of this field returns the state of the lock (0=unlocked, 1=locked).
